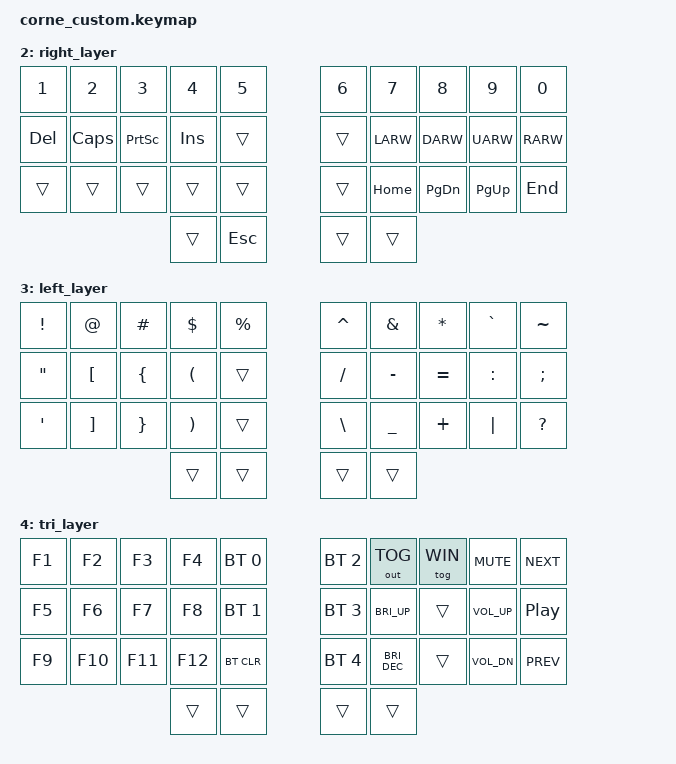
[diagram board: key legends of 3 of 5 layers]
// Copyright (c) 2022 The ZMK Contributors
// SPDX-License-Identifier: MIT

// fork from: https://github.com/SethuEapen/zmk-sweep-updated/blob/main/config/cradio.keymap
// zmk docs: https://zmk.dev/docs/user-setup


#include <behaviors.dtsi>
#include <dt-bindings/zmk/keys.h>
#include <dt-bindings/zmk/bt.h>
#include <dt-bindings/zmk/outputs.h>

// Home row mods macro
#define HRML(k2,k3,k4) &ht LALT k2  &ht LCTRL k3  &ht LGUI k4
#define HRMR(k1,k2,k3) &ht RGUI k1  &ht RCTRL k2  &ht RALT k3
#define WHRML(k2,k3,k4) &ht LALT k2  &ht LGUI k3  &ht LCTRL k4
#define WHRMR(k1,k2,k3) &ht RCTRL k1  &ht RGUI k2  &ht RALT k3

#define MAC 0
#define WIN 1
#define RIG 2
#define LEF 3
#define TRI 4

/ {
    behaviors {
        ht: hold_tap {
            label = "hold_tap";
            compatible = "zmk,behavior-hold-tap";
            #binding-cells = <2>;
            flavor = "tap-preferred";
            tapping-term-ms = <220>;
            quick-tap-ms = <150>;
            global-quick-tap;
            bindings = <&kp>, <&kp>;
        };

        // copy on double tap of c
        dtc: double_tap_copy {
            compatible = "zmk,behavior-double-tap";
            label = "double_tap_copy";
            #binding-cells = <1>;
            tapping-term-ms = <200>;
            bindings = <&copy>;
        };
    };

    macros {
        copy: copy {
            compatible = "zmk,behavior-macro";
            label = "copy";
            #binding-cells = <0>;
            wait-ms = <30>;
            tap-ms = <40>;
            bindings = <&kp LCTRL &kp C>;
        };
    };

    conditional_layers {
        compatible = "zmk,conditional-layers";
        tri_layer {
            if-layers = <RIG LEF>;
            then-layer = <TRI>;
        };
    };

    keymap {
        compatible = "zmk,keymap";
        default_layer {
            bindings = <
        //╭──────────┬──────────┬──────────┬──────────┬──────────┬──────────╮   ╭──────────┬──────────┬──────────┬──────────┬──────────┬──────────╮
        //│          │  Q       │  W       │  E       │  R       │  T       │   │  Z       │  U       │  I       │  O       │  P       │          │
            &trans     &kp Q      &kp W      &kp E      &kp R      &kp T          &kp Z      &kp U      &kp I      &kp O      &kp P      &trans
        //├──────────┼──────────┼──────────┼──────────┼──────────┼──────────┤   ├──────────┼──────────┼──────────┼──────────┼──────────┼──────────┤
        //│          │  A       │  S       │  D       │  F       │  G       │   │  H       │  J       │  K       │  L       │BACKSPACE │          │
            &trans     &kp A     HRML(S,         D,         F)     &kp G          &kp H      HRMR(J,        K,           L)    &kp BSPC  &trans
        //├──────────┼──────────┼──────────┼──────────┼──────────┼──────────┤   ├──────────┼──────────┼──────────┼──────────┼──────────┼──────────┤
        //│          │  Y       │  X       │  C       │  V       │  B       │   │  N       │  M       │ , <      │ . >      │ ENTER    │          │
            &trans     &kp Y      &kp X      &kp C      &kp V      &kp B          &kp N      &kp M      &kp COMMA  &kp DOT    &kp ENTER  &trans
        //╰──────────┴──────────┴──────────┼──────────┼──────────┼──────────┼   ├──────────├──────────┼──────────┼──────────┴──────────┴──────────╯
                                              &trans   &lt LEF TAB &kp LSHIFT    &kp SPACE  &lt RIG TAB  &trans
        //                                 ╰──────────┴──────────┴──────────╯   ╰──────────┴──────────┴──────────╯
            >;
        };

        windows_layer {
            bindings = <
        //╭──────────┬──────────┬──────────┬──────────┬──────────┬──────────╮   ╭──────────┬──────────┬──────────┬──────────┬──────────┬──────────╮
        //│          │  Q       │  W       │  E       │  R       │  T       │   │  Z       │  U       │  I       │  O       │  P       │          │
            &trans     &kp Q      &kp W      &kp E      &kp R      &kp T          &kp Z      &kp U      &kp I      &kp O      &kp P      &trans
        //├──────────┼──────────┼──────────┼──────────┼──────────┼──────────┤   ├──────────┼──────────┼──────────┼──────────┼──────────┼──────────┤
        //│          │  A       │  S       │  D       │  F       │  G       │   │  H       │  J       │  K       │  L       │BACKSPACE │          │
            &trans     &kp A     WHRML(S,         D,        F)     &kp G          &kp H     WHRMR(J,        K,         L)    &kp BSPC  &trans
        //├──────────┼──────────┼──────────┼──────────┼──────────┼──────────┤   ├──────────┼──────────┼──────────┼──────────┼──────────┼──────────┤
        //│          │  Y       │  X       │  C       │  V       │  B       │   │  N       │  M       │ , <      │ . >      │ ENTER    │          │
            &trans     &kp Y      &kp X      &kp C      &kp V      &kp B          &kp N      &kp M      &kp COMMA  &kp DOT    &kp ENTER  &trans
        //╰──────────┴──────────┴──────────┼──────────┼──────────┼──────────┼   ├──────────├──────────┼──────────┼──────────┴──────────┴──────────╯
                                              &trans  &lt LEF TAB  &kp LSHIFT    &kp SPACE  &lt RIG TAB  &trans
        //                                 ╰──────────┴──────────┴──────────╯   ╰──────────┴──────────┴──────────╯
            >;
        };

        right_layer {
            bindings = <
        //╭──────────┬──────────┬──────────┬──────────┬──────────╮   ╭──────────┬──────────┬──────────┬──────────┬──────────╮
        //│ 1        │  2       │  3       │  4       │  5       │   │ 6        │ 7        │ 8        │ 9        │   0      │
            &kp N1     &kp N2     &kp N3     &kp N4     &kp N5         &kp N6     &kp N7     &kp N8     &kp N9     &kp N0
        //├──────────┼──────────┼──────────┼──────────┼──────────┤   ├──────────┼──────────┼──────────┼──────────┼──────────┤
        //│ DELETE   │ CapsLock │ PrintSc  │  INSERT  │          |   |          │ LEFT     │ DOWN     │ UP       │ RIGHT    │
            &kp DEL    &kp CAPS   &kp PSCRN  &kp INS     &trans         &trans    &kp LARW   &kp DARW   &kp UARW   &kp RARW 
        //├──────────┼──────────┼──────────┼──────────┼──────────┤   ├──────────┼──────────┼──────────┼──────────┼──────────┤
        //│          │          │          │          │          │   │          │ HOME     │ PAGE DN  │ PAGE UP  │ END      │
            &trans    &trans     &trans     &trans      &trans          &trans    &kp HOME   &kp PG_DN  &kp PG_UP  &kp END 
        //╰──────────┴──────────┴──────────┼──────────┼──────────┤   ├──────────┼──────────┼──────────┴──────────┴──────────╯
                                             &trans     &kp ESC        &trans     &trans
        //                                 ╰──────────┴──────────╯   ╰──────────┴──────────╯
            >;
        };

        left_layer {
            bindings = <
        //╭──────────┬──────────┬──────────┬──────────┬──────────╮   ╭──────────┬──────────┬──────────┬──────────┬──────────╮
        //│  !       │  @       │  #       │  $       │  %       │   │  ^       │  &       │  *       │  `       │  ~       │
            &kp EXCL   &kp AT     &kp HASH   &kp DLLR   &kp PRCNT      &kp CARET  &kp AMPS   &kp ASTRK  &kp GRAVE   &kp TILDE
        //├──────────┼──────────┼──────────┼──────────┼──────────┤   ├──────────┼──────────┼──────────┼──────────┼──────────┤
        //│  "       │  [       │  {       │  (       │          │   │   /      │  -       │  =       │     :    │  ;       │
            &kp DQT  &kp LBKT   &kp LBRC   &kp LPAR   &trans         &kp FSLH   &kp MINUS  &kp EQUAL  &kp COLON   &kp SEMI
        //├──────────┼──────────┼──────────┼──────────┼──────────┤   ├──────────┼──────────┼──────────┼──────────┼──────────┤
        //│  '       │  ]       │  }       │  )       │          │   │    \     │  _       │  +       │  │       │   ?      │
            &kp SQT     &kp RBKT   &kp RBRC   &kp RPAR   &trans         &kp BSLH   &kp UNDER  &kp PLUS   &kp PIPE  &kp QMARK
        //╰──────────┴──────────┴──────────┼──────────┼──────────┤   ├──────────┼──────────┼──────────┴──────────┴──────────╯
                                             &trans     &trans         &trans     &trans
        //                                 ╰──────────┴──────────╯   ╰──────────┴──────────╯
            >;
        };

        tri_layer {
            bindings = <
        //╭──────────┬──────────┬──────────┬───────────┬────────────╮   ╭────────────┬────────────┬──────────┬───────────┬──────────╮
        //│  F1      │  F2      │  F3      │  F4       │ PROFILE 0  │   │ PROFILE 2  │ TOGGLEOUT  │ WINDOWS  │ VOL MUTE  │ NEXTSONG │
            &kp F1     &kp F2     &kp F3     &kp F4     &bt BT_SEL 0     &bt BT_SEL 2  &out OUT_TOG &tog WIN  &kp C_MUTE  &kp C_NEXT
        //├──────────┼──────────┼──────────┼───────────┼────────────┤   ├────────────┼────────────┼──────────┼───────────┼──────────┤
        //│  F5      │  F6      │  F7      │  F8       │ PROFILE 1  │   │ PROFILE 3  │ INC BRIGHT │          │  VOL UP   │PAUSEMUSIC│
            &kp F5     &kp F6     &kp F7     &kp F8     &bt BT_SEL 1     &bt BT_SEL 3  &kp C_BRI_UP  &trans   &kp C_VOL_UP  &kp C_PP
        //├──────────┼──────────┼──────────┼───────────┼────────────┤   ├────────────┼────────────┼──────────┼───────────┼──────────┤
        //│  F9      │  F10     │  F11     │  F12      │  CLEAR BT  │   │ PROFILE 4  │ DEC BRIGHT │          |  VOL DOWN │ PREVSONG │
            &kp F9     &kp F10    &kp F11    &kp F12     &bt BT_CLR      &bt BT_SEL 4  &kp C_BRI_DEC  &trans   &kp C_VOL_DN &kp C_PREV
        //╰──────────┴──────────┴──────────┼───────────┼────────────┤   ├────────────┼────────────┼──────────┴───────────┴──────────╯
                                                &trans     &trans         &trans     &trans
        //                                  ╰───────────┴──────────╯   ╰──────────┴────────────╯
            >;
        };
    };
};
